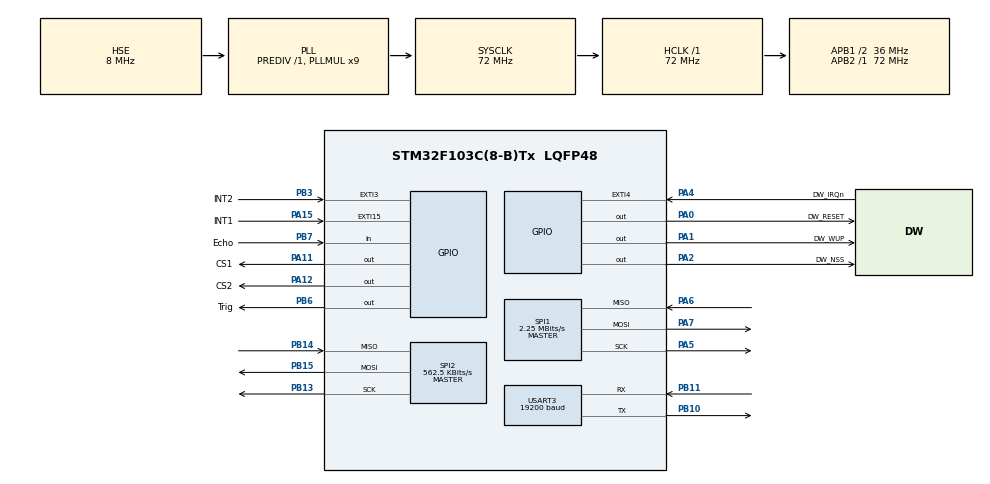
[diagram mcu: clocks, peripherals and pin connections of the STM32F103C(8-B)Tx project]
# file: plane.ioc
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Dma.Request0=SPI2_RX
Dma.Request1=SPI2_TX
Dma.SPI2_RX.0.Direction=DMA_PERIPH_TO_MEMORY
Dma.SPI2_RX.0.Instance=DMA1_Channel4
Dma.SPI2_RX.0.MemDataAlignment=DMA_MDATAALIGN_BYTE
Dma.SPI2_RX.0.MemInc=DMA_MINC_ENABLE
Dma.SPI2_RX.0.Mode=DMA_NORMAL
Dma.SPI2_RX.0.PeriphDataAlignment=DMA_PDATAALIGN_BYTE
Dma.SPI2_RX.0.PeriphInc=DMA_PINC_DISABLE
Dma.SPI2_RX.0.Priority=DMA_PRIORITY_VERY_HIGH
Dma.SPI2_TX.1.Direction=DMA_MEMORY_TO_PERIPH
Dma.SPI2_TX.1.Instance=DMA1_Channel5
Dma.SPI2_TX.1.MemDataAlignment=DMA_MDATAALIGN_BYTE
Dma.SPI2_TX.1.MemInc=DMA_MINC_ENABLE
Dma.SPI2_TX.1.Mode=DMA_NORMAL
Dma.SPI2_TX.1.PeriphDataAlignment=DMA_PDATAALIGN_BYTE
Dma.SPI2_TX.1.PeriphInc=DMA_PINC_DISABLE
Dma.SPI2_TX.1.Priority=DMA_PRIORITY_HIGH
FREERTOS.Tasks01=defaultTask,0,128,StartDefaultTask,Default,NULL,Dynamic,NULL,NULL
FREERTOS.configTOTAL_HEAP_SIZE=12000
Mcu.Family=STM32F1
Mcu.Name=STM32F103C(8-B)Tx
Mcu.Package=LQFP48
NVIC.DMA1_Channel4_IRQn=true\:5\:0\:false\:false\:true\:true\:false\:true\:true
NVIC.DMA1_Channel5_IRQn=true\:5\:0\:false\:false\:true\:true\:false\:true\:true
NVIC.EXTI15_10_IRQn=true\:5\:0\:false\:false\:true\:true\:true\:true\:true
NVIC.EXTI3_IRQn=true\:5\:0\:false\:false\:true\:true\:true\:true\:true
NVIC.PriorityGroup=NVIC_PRIORITYGROUP_4
NVIC.TIM2_IRQn=true\:5\:0\:false\:false\:true\:true\:true\:true\:true
NVIC.TIM3_IRQn=true\:5\:0\:false\:false\:true\:true\:true\:true\:true
NVIC.TIM4_IRQn=true\:15\:0\:false\:false\:true\:false\:false\:true\:true
NVIC.TimeBase=TIM4_IRQn
NVIC.TimeBaseIP=TIM4
PA0-WKUP.GPIO_Label=DW_RESET
PA0-WKUP.GPIO_ModeDefaultOutputPP=GPIO_MODE_OUTPUT_OD
PA0-WKUP.GPIO_PuPd=GPIO_NOPULL
PA0-WKUP.GPIO_Speed=GPIO_SPEED_FREQ_HIGH
PA0-WKUP.Signal=GPIO_Output
PA1.GPIO_Label=DW_WUP
PA1.GPIO_ModeDefaultOutputPP=GPIO_MODE_OUTPUT_OD
PA1.GPIO_PuPd=GPIO_NOPULL
PA1.GPIO_Speed=GPIO_SPEED_FREQ_HIGH
PA1.PinState=GPIO_PIN_SET
PA1.Signal=GPIO_Output
PA11.GPIO_Label=CS1
PA11.GPIO_PuPd=GPIO_PULLUP
PA11.GPIO_Speed=GPIO_SPEED_FREQ_HIGH
PA11.PinState=GPIO_PIN_SET
PA11.Signal=GPIO_Output
PA12.GPIO_Label=CS2
PA12.GPIO_PuPd=GPIO_PULLUP
PA12.GPIO_Speed=GPIO_SPEED_FREQ_HIGH
PA12.PinState=GPIO_PIN_SET
PA12.Signal=GPIO_Output
PA13.Mode=Serial_Wire
PA13.Signal=SYS_JTMS-SWDIO
PA14.Mode=Serial_Wire
PA14.Signal=SYS_JTCK-SWCLK
PA15.GPIO_Label=INT1
PA15.GPIO_ModeDefaultEXTI=GPIO_MODE_IT_RISING
PA15.Signal=GPXTI15
PA2.GPIO_Label=DW_NSS
PA2.GPIO_Speed=GPIO_SPEED_FREQ_HIGH
PA2.PinState=GPIO_PIN_SET
PA2.Signal=GPIO_Output
PA4.GPIO_Label=DW_IRQn
PA4.GPIO_PuPd=GPIO_PULLDOWN
PA4.Signal=GPXTI4
PA5.Mode=Full_Duplex_Master
PA5.Signal=SPI1_SCK
PA6.Mode=Full_Duplex_Master
PA6.Signal=SPI1_MISO
PA7.Mode=Full_Duplex_Master
PA7.Signal=SPI1_MOSI
PB10.Mode=Asynchronous
PB10.Signal=USART3_TX
PB11.Mode=Asynchronous
PB11.Signal=USART3_RX
PB13.Mode=Full_Duplex_Master
PB13.Signal=SPI2_SCK
PB14.Mode=Full_Duplex_Master
PB14.Signal=SPI2_MISO
PB15.Mode=Full_Duplex_Master
PB15.Signal=SPI2_MOSI
PB3.GPIO_Label=INT2
PB3.Signal=GPXTI3
PB6.GPIO_Label=Trig
PB6.GPIO_ModeDefaultOutputPP=GPIO_MODE_OUTPUT_PP
PB6.GPIO_PuPd=GPIO_NOPULL
PB6.GPIO_Speed=GPIO_SPEED_FREQ_MEDIUM
PB6.PinState=GPIO_PIN_RESET
PB6.Signal=GPIO_Output
PB7.GPIO_Label=Echo
PB7.GPIO_PuPd=GPIO_PULLUP
PB7.Signal=GPIO_Input
PC14-OSC32_IN.Mode=LSE-External-Oscillator
PC14-OSC32_IN.Signal=RCC_OSC32_IN
PC15-OSC32_OUT.Mode=LSE-External-Oscillator
PC15-OSC32_OUT.Signal=RCC_OSC32_OUT
PD0-OSC_IN.Mode=HSE-External-Oscillator
PD0-OSC_IN.Signal=RCC_OSC_IN
PD1-OSC_OUT.Mode=HSE-External-Oscillator
PD1-OSC_OUT.Signal=RCC_OSC_OUT
ProjectManager.HeapSize=0x200
ProjectManager.StackSize=0x400
ProjectManager.TargetToolchain=Makefile
RCC.AHBFreq_Value=72000000
RCC.APB1CLKDivider=RCC_HCLK_DIV2
RCC.APB1Freq_Value=36000000
RCC.APB1TimFreq_Value=72000000
RCC.APB2Freq_Value=72000000
RCC.APB2TimFreq_Value=72000000
RCC.HCLKFreq_Value=72000000
RCC.PLLMUL=RCC_PLL_MUL9
RCC.PLLSourceVirtual=RCC_PLLSOURCE_HSE
RCC.SYSCLKFreq_VALUE=72000000
RCC.SYSCLKSource=RCC_SYSCLKSOURCE_PLLCLK
RCC.USBFreq_Value=72000000
SPI1.BaudRatePrescaler=SPI_BAUDRATEPRESCALER_32
SPI1.CalculateBaudRate=2.25 MBits/s
SPI1.Direction=SPI_DIRECTION_2LINES
SPI1.Mode=SPI_MODE_MASTER
SPI1.VirtualType=VM_MASTER
SPI2.BaudRatePrescaler=SPI_BAUDRATEPRESCALER_64
SPI2.CLKPhase=SPI_PHASE_2EDGE
SPI2.CLKPolarity=SPI_POLARITY_HIGH
SPI2.CalculateBaudRate=562.5 KBits/s
SPI2.Direction=SPI_DIRECTION_2LINES
SPI2.Mode=SPI_MODE_MASTER
SPI2.VirtualType=VM_MASTER
STMicroelectronics.X-CUBE-ALGOBUILD.1.3.0.LibraryCcDSPOoLibraryJjDSPOoLibrary=true
TIM1.AutoReloadPreload=TIM_AUTORELOAD_PRELOAD_ENABLE
TIM1.Period=999
TIM1.Prescaler=71
TIM2.AutoReloadPreload=TIM_AUTORELOAD_PRELOAD_ENABLE
TIM2.Period=9999
TIM2.Prescaler=7199
TIM3.AutoReloadPreload=TIM_AUTORELOAD_PRELOAD_ENABLE
TIM3.Period=9999
TIM3.Prescaler=71
USART3.BaudRate=19200
USART3.VirtualMode=VM_ASYNC
VP_FREERTOS_VS_CMSIS_V1.Mode=CMSIS_V1
VP_STMicroelectronics.X-CUBE-ALGOBUILD_VS_DSPOoLibraryJjLibrary_1.3.0_1.3.0.Mode=DSPOoLibraryJjLibrary
VP_SYS_VS_tim4.Mode=TIM4
VP_TIM1_VS_ClockSourceINT.Mode=Internal
VP_TIM2_VS_ClockSourceINT.Mode=Internal
VP_TIM3_VS_ClockSourceINT.Mode=Internal
board=custom

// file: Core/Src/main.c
/* USER CODE BEGIN Header */
/**
  ******************************************************************************
  * @file           : main.c
  * @brief          : Main program body
  ******************************************************************************
  * @attention
  *
  * Copyright (c) 2024 STMicroelectronics.
  * All rights reserved.
  *
  * This software is licensed under terms that can be found in the LICENSE file
  * in the root directory of this software component.
  * If no LICENSE file comes with this software, it is provided AS-IS.
  *
  ******************************************************************************
  */
/* USER CODE END Header */
#include "main.h"
#include "cmsis_os.h"
#include "dma.h"
#include "spi.h"
#include "tim.h"
#include "usart.h"
#include "gpio.h"

/* USER CODE BEGIN Includes */
#include "BMI088driver.h"
#include "plane.h"
#include "ex_05a_main.h"
/* USER CODE END Includes */

void SystemClock_Config(void);
void MX_FREERTOS_Init(void);
/* USER CODE BEGIN PFP */
uint8_t second;   //秒计数器
/* USER CODE END PFP */

int main(void)
{

  /* MCU Configuration--------------------------------------------------------*/

  /* Reset of all peripherals, Initializes the Flash interface and the Systick. */
  HAL_Init();

  /* Configure the system clock */
  SystemClock_Config();

  /* Initialize all configured peripherals */
  MX_GPIO_Init();
  MX_DMA_Init();
  MX_SPI2_Init();
  MX_SPI1_Init();
  MX_TIM2_Init();
  MX_USART3_UART_Init();
  MX_TIM3_Init();
  MX_TIM1_Init();
  /* USER CODE BEGIN 2 */
  PlaneInit();
  // __HAL_TIM_ENABLE(&htim2);
  /* USER CODE END 2 */

  /* Call init function for freertos objects (in cmsis_os2.c) */
  MX_FREERTOS_Init();

  /* Start scheduler */
  osKernelStart();

  /* We should never get here as control is now taken by the scheduler */

  /* Infinite loop */
  while (1)
  {

  }
}

void SystemClock_Config(void)
{
  RCC_OscInitTypeDef RCC_OscInitStruct = {0};
  RCC_ClkInitTypeDef RCC_ClkInitStruct = {0};

  /** Initializes the RCC Oscillators according to the specified parameters
  * in the RCC_OscInitTypeDef structure.
  */
  RCC_OscInitStruct.OscillatorType = RCC_OSCILLATORTYPE_HSE;
  RCC_OscInitStruct.HSEState = RCC_HSE_ON;
  RCC_OscInitStruct.HSEPredivValue = RCC_HSE_PREDIV_DIV1;
  RCC_OscInitStruct.HSIState = RCC_HSI_ON;
  RCC_OscInitStruct.PLL.PLLState = RCC_PLL_ON;
  RCC_OscInitStruct.PLL.PLLSource = RCC_PLLSOURCE_HSE;
  RCC_OscInitStruct.PLL.PLLMUL = RCC_PLL_MUL9;
  if (HAL_RCC_OscConfig(&RCC_OscInitStruct) != HAL_OK)
  {
    Error_Handler();
  }

  /** Initializes the CPU, AHB and APB buses clocks
  */
  RCC_ClkInitStruct.ClockType = RCC_CLOCKTYPE_HCLK|RCC_CLOCKTYPE_SYSCLK
                              |RCC_CLOCKTYPE_PCLK1|RCC_CLOCKTYPE_PCLK2;
  RCC_ClkInitStruct.SYSCLKSource = RCC_SYSCLKSOURCE_PLLCLK;
  RCC_ClkInitStruct.AHBCLKDivider = RCC_SYSCLK_DIV1;
  RCC_ClkInitStruct.APB1CLKDivider = RCC_HCLK_DIV2;
  RCC_ClkInitStruct.APB2CLKDivider = RCC_HCLK_DIV1;

  if (HAL_RCC_ClockConfig(&RCC_ClkInitStruct, FLASH_LATENCY_2) != HAL_OK)
  {
    Error_Handler();
  }
}

void HAL_TIM_PeriodElapsedCallback(TIM_HandleTypeDef *htim)
{
  if (htim->Instance == TIM4) {
    HAL_IncTick();
  }

  /* 逐步推进状态机 */
  if(htim->Instance == TIM2)
  {
    if(finish==1)second++;
    if(second==2&&finish==1)
    {
      second=0;
      finish=2;
    }

    if(finish==2)second++;
    if(second==5&&finish==2)
    {
      second=0;
      finish=3;
    }

    if(finish==3)second++; //越过圆环之后前进时间
    if(second==2&&finish==3)
    {
      second=0;
      finish=4;
    }

    if(finish==4)second++;
    if(second==2&&finish==4)
    {
      second=0;
      finish=5;
    }
  }
  /* USER CODE END Callback 1 */
}

void Error_Handler(void)
{
  __disable_irq();
  while (1)
  {
  }
}

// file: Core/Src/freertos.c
/* USER CODE BEGIN Header */
/**
  ******************************************************************************
  * File Name          : freertos.c
  * Description        : Code for freertos applications
  ******************************************************************************
  * @attention
  *
  * Copyright (c) 2024 STMicroelectronics.
  * All rights reserved.
  *
  * This software is licensed under terms that can be found in the LICENSE file
  * in the root directory of this software component.
  * If no LICENSE file comes with this software, it is provided AS-IS.
  *
  ******************************************************************************
  */
/* USER CODE END Header */

#include "FreeRTOS.h"
#include "task.h"
#include "main.h"
#include "cmsis_os.h"

osThreadId defaultTaskHandle;

void StartDefaultTask(void const * argument);

void MX_FREERTOS_Init(void); /* (MISRA C 2004 rule 8.1) */

/* GetIdleTaskMemory prototype (linked to static allocation support) */
void vApplicationGetIdleTaskMemory( StaticTask_t **ppxIdleTaskTCBBuffer, StackType_t **ppxIdleTaskStackBuffer, uint32_t *pulIdleTaskStackSize );

/* USER CODE BEGIN GET_IDLE_TASK_MEMORY */
static StaticTask_t xIdleTaskTCBBuffer;
static StackType_t xIdleStack[configMINIMAL_STACK_SIZE];

void vApplicationGetIdleTaskMemory( StaticTask_t **ppxIdleTaskTCBBuffer, StackType_t **ppxIdleTaskStackBuffer, uint32_t *pulIdleTaskStackSize )
{
  *ppxIdleTaskTCBBuffer = &xIdleTaskTCBBuffer;
  *ppxIdleTaskStackBuffer = &xIdleStack[0];
  *pulIdleTaskStackSize = configMINIMAL_STACK_SIZE;
  /* place for user code */
}
/* USER CODE END GET_IDLE_TASK_MEMORY */

void MX_FREERTOS_Init(void) {

  /* Create the thread(s) */
  /* definition and creation of defaultTask */
  osThreadDef(defaultTask, StartDefaultTask, osPriorityNormal, 0, 128);
  defaultTaskHandle = osThreadCreate(osThread(defaultTask), NULL);

}

void StartDefaultTask(void const * argument)
{
  /* USER CODE BEGIN StartDefaultTask */
  /* Infinite loop */
  for(;;)
  {
    osThreadTerminate(defaultTaskHandle);

    osDelay(100);
  }
  /* USER CODE END StartDefaultTask */
}
